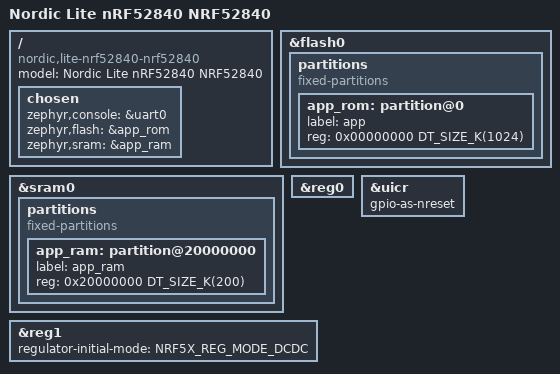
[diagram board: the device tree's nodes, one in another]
/*
 * Copyright (c) 2025 Nordic Semiconductor ASA
 *
 * SPDX-License-Identifier: Apache-2.0
 */

/dts-v1/;
#include <nordic/nrf52840_qiaa.dtsi>
#include <nordic/nrf52840_partition.dtsi>
#include <zephyr/dt-bindings/input/input-event-codes.h>

/ {
	model = "Nordic Lite nRF52840 NRF52840";
	compatible = "nordic,lite-nrf52840-nrf52840";

	chosen {
		zephyr,console = &uart0;
		zephyr,flash = &app_rom;
		zephyr,sram = &app_ram;
	};
};

&flash0 {
	partitions {
		compatible = "fixed-partitions";
		#address-cells = <1>;
		#size-cells = <1>;
		app_rom: partition@0 {
			label = "app";
			reg = <0x00000000 DT_SIZE_K(1024)>;
		};
	};
};

&sram0 {
	partitions {
		compatible = "fixed-partitions";
		#address-cells = <1>;
		#size-cells = <1>;

		app_ram: partition@20000000 {
			label = "app_ram";
			reg = <0x20000000 DT_SIZE_K(200)>;
		};
	};
};

&reg0 {
	status = "okay";
};

&reg1 {
	regulator-initial-mode = <NRF5X_REG_MODE_DCDC>;
};

&uicr {
	gpio-as-nreset;
};
